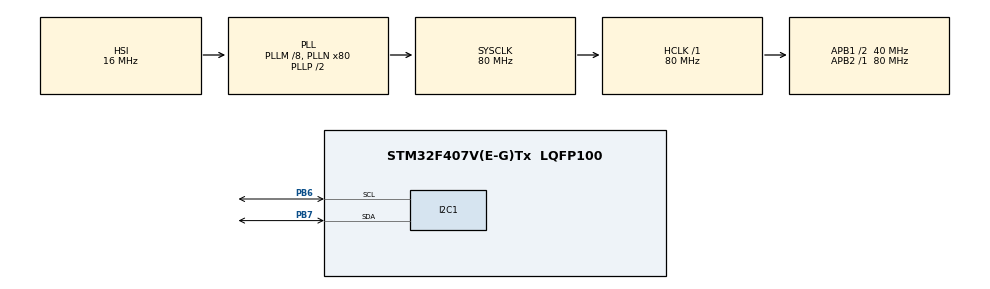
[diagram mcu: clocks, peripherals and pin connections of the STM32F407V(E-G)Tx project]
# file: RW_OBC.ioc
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Mcu.Family=STM32F4
Mcu.Name=STM32F407V(E-G)Tx
Mcu.Package=LQFP100
NVIC.PriorityGroup=NVIC_PRIORITYGROUP_4
PB6.Mode=I2C
PB6.Signal=I2C1_SCL
PB7.Mode=I2C
PB7.Signal=I2C1_SDA
ProjectManager.HeapSize=0x2000
ProjectManager.StackSize=0x4000
ProjectManager.TargetToolchain=STM32CubeIDE
RCC.48MHZClocksFreq_Value=22857142.85714286
RCC.AHBFreq_Value=80000000
RCC.APB1CLKDivider=RCC_HCLK_DIV2
RCC.APB1Freq_Value=40000000
RCC.APB1TimFreq_Value=80000000
RCC.APB2Freq_Value=80000000
RCC.APB2TimFreq_Value=80000000
RCC.CortexFreq_Value=80000000
RCC.HCLKFreq_Value=80000000
RCC.HSE_VALUE=8000000
RCC.HSI_VALUE=16000000
RCC.LSE_VALUE=32768
RCC.PLLM=8
RCC.PLLN=80
RCC.PLLQ=7
RCC.SYSCLKFreq_VALUE=80000000
RCC.SYSCLKSource=RCC_SYSCLKSOURCE_PLLCLK
RCC.VCOOutputFreq_Value=160000000
TIM1.Channel-Output\ Compare1\ No\ Output=TIM_CHANNEL_1
TIM1.Period=65536-1
TIM1.Prescaler=80-1
VP_TIM1_VS_no_output1.Mode=Output Compare1 No Output
board=custom

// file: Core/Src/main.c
/* USER CODE BEGIN Header */
/**
  ******************************************************************************
  * @file           : main.c
  * @brief          : Main program body
  ******************************************************************************
  * @attention
  *
  * <h2><center>&copy; Copyright (c) 2021 STMicroelectronics.
  * All rights reserved.</center></h2>
  *
  * This software component is licensed by ST under BSD 3-Clause license,
  * the "License"; You may not use this file except in compliance with the
  * License. You may obtain a copy of the License at:
  *                        opensource.org/licenses/BSD-3-Clause
  *
  ******************************************************************************
  */
/* USER CODE END Header */
#include "main.h"

I2C_HandleTypeDef hi2c1;

TIM_HandleTypeDef htim1;

/* USER CODE BEGIN PV */
L3GD20H_Type gyro;
HMC5883L_Type magn;
double psi;
double phi;
double test;
double theta;
Quaternion_Type q;
Rotation_Matrix_Type r;
/* USER CODE END PV */

void SystemClock_Config(void);
static void MX_GPIO_Init(void);
static void MX_I2C1_Init(void);
static void MX_TIM1_Init(void);

int main(void)
{

  /* MCU Configuration--------------------------------------------------------*/

  /* Reset of all peripherals, Initializes the Flash interface and the Systick. */
  HAL_Init();

  /* USER CODE BEGIN Init */

  float dt=0;
  /* USER CODE END Init */

  /* Configure the system clock */
  SystemClock_Config();

  /* Initialize all configured peripherals */
  MX_GPIO_Init();
  MX_I2C1_Init();
  MX_TIM1_Init();
  /* USER CODE BEGIN 2 */

  L3GD20H_Init(&gyro,hi2c1, L3GD20H_DR_200 ,L3GD20H_FR_250, L3GD20H_BW_3,L3GD20H_NORMAL,L3GD20H_LOW_ODR_D);
  HAL_TIM_Base_Start(&htim1);
  L3GD20H_Calibration(&gyro,htim1);

  /* USER CODE END 2 */

  /* Infinite loop */
  /* USER CODE BEGIN WHILE */
  __HAL_TIM_SET_COUNTER(&htim1, 0);
  HAL_Delay(10);
  while (1)
  {
    /* USER CODE END WHILE */

    /* USER CODE BEGIN 3 */
    dt=__HAL_TIM_GET_COUNTER(&htim1);
    dt=dt*0.000001;
	__HAL_TIM_SET_COUNTER(&htim1, 0);
	//  HMC5883L_Init(&magn,hi2c1);
	L3GD20H_Read(&gyro,dt);
	psi=gyro.angle[0]*3.1416/180;
	theta=gyro.angle[1]*3.1416/180;
	phi=gyro.angle[2]*3.1416/180;
	r=ADCS_RPY2RotationMatrix(phi,theta,psi);
	test=sqrt(r.r11+r.r22+r.r33+1);
	q=ADCS_RotationMatrix2Quaternion(&r);
	//HIL_Transmit_Gyro(&gyro);
	HAL_Delay(10);
  }
  /* USER CODE END 3 */
}

void SystemClock_Config(void)
{
  RCC_OscInitTypeDef RCC_OscInitStruct = {0};
  RCC_ClkInitTypeDef RCC_ClkInitStruct = {0};

  /** Configure the main internal regulator output voltage
  */
  __HAL_RCC_PWR_CLK_ENABLE();
  __HAL_PWR_VOLTAGESCALING_CONFIG(PWR_REGULATOR_VOLTAGE_SCALE1);
  /** Initializes the RCC Oscillators according to the specified parameters
  * in the RCC_OscInitTypeDef structure.
  */
  RCC_OscInitStruct.OscillatorType = RCC_OSCILLATORTYPE_HSI;
  RCC_OscInitStruct.HSIState = RCC_HSI_ON;
  RCC_OscInitStruct.HSICalibrationValue = RCC_HSICALIBRATION_DEFAULT;
  RCC_OscInitStruct.PLL.PLLState = RCC_PLL_ON;
  RCC_OscInitStruct.PLL.PLLSource = RCC_PLLSOURCE_HSI;
  RCC_OscInitStruct.PLL.PLLM = 8;
  RCC_OscInitStruct.PLL.PLLN = 80;
  RCC_OscInitStruct.PLL.PLLP = RCC_PLLP_DIV2;
  RCC_OscInitStruct.PLL.PLLQ = 7;
  if (HAL_RCC_OscConfig(&RCC_OscInitStruct) != HAL_OK)
  {
    Error_Handler();
  }
  /** Initializes the CPU, AHB and APB buses clocks
  */
  RCC_ClkInitStruct.ClockType = RCC_CLOCKTYPE_HCLK|RCC_CLOCKTYPE_SYSCLK
                              |RCC_CLOCKTYPE_PCLK1|RCC_CLOCKTYPE_PCLK2;
  RCC_ClkInitStruct.SYSCLKSource = RCC_SYSCLKSOURCE_PLLCLK;
  RCC_ClkInitStruct.AHBCLKDivider = RCC_SYSCLK_DIV1;
  RCC_ClkInitStruct.APB1CLKDivider = RCC_HCLK_DIV2;
  RCC_ClkInitStruct.APB2CLKDivider = RCC_HCLK_DIV1;

  if (HAL_RCC_ClockConfig(&RCC_ClkInitStruct, FLASH_LATENCY_2) != HAL_OK)
  {
    Error_Handler();
  }
}

static void MX_I2C1_Init(void)
{

  hi2c1.Instance = I2C1;
  hi2c1.Init.ClockSpeed = 100000;
  hi2c1.Init.DutyCycle = I2C_DUTYCYCLE_2;
  hi2c1.Init.OwnAddress1 = 0;
  hi2c1.Init.AddressingMode = I2C_ADDRESSINGMODE_7BIT;
  hi2c1.Init.DualAddressMode = I2C_DUALADDRESS_DISABLE;
  hi2c1.Init.OwnAddress2 = 0;
  hi2c1.Init.GeneralCallMode = I2C_GENERALCALL_DISABLE;
  hi2c1.Init.NoStretchMode = I2C_NOSTRETCH_DISABLE;
  if (HAL_I2C_Init(&hi2c1) != HAL_OK)
  {
    Error_Handler();
  }

}

static void MX_TIM1_Init(void)
{

  TIM_MasterConfigTypeDef sMasterConfig = {0};
  TIM_OC_InitTypeDef sConfigOC = {0};
  TIM_BreakDeadTimeConfigTypeDef sBreakDeadTimeConfig = {0};

  htim1.Instance = TIM1;
  htim1.Init.Prescaler = 80-1;
  htim1.Init.CounterMode = TIM_COUNTERMODE_UP;
  htim1.Init.Period = 65536-1;
  htim1.Init.ClockDivision = TIM_CLOCKDIVISION_DIV1;
  htim1.Init.RepetitionCounter = 0;
  htim1.Init.AutoReloadPreload = TIM_AUTORELOAD_PRELOAD_DISABLE;
  if (HAL_TIM_OC_Init(&htim1) != HAL_OK)
  {
    Error_Handler();
  }
  sMasterConfig.MasterOutputTrigger = TIM_TRGO_RESET;
  sMasterConfig.MasterSlaveMode = TIM_MASTERSLAVEMODE_DISABLE;
  if (HAL_TIMEx_MasterConfigSynchronization(&htim1, &sMasterConfig) != HAL_OK)
  {
    Error_Handler();
  }
  sConfigOC.OCMode = TIM_OCMODE_TIMING;
  sConfigOC.Pulse = 0;
  sConfigOC.OCPolarity = TIM_OCPOLARITY_HIGH;
  sConfigOC.OCNPolarity = TIM_OCNPOLARITY_HIGH;
  sConfigOC.OCFastMode = TIM_OCFAST_DISABLE;
  sConfigOC.OCIdleState = TIM_OCIDLESTATE_RESET;
  sConfigOC.OCNIdleState = TIM_OCNIDLESTATE_RESET;
  if (HAL_TIM_OC_ConfigChannel(&htim1, &sConfigOC, TIM_CHANNEL_1) != HAL_OK)
  {
    Error_Handler();
  }
  sBreakDeadTimeConfig.OffStateRunMode = TIM_OSSR_DISABLE;
  sBreakDeadTimeConfig.OffStateIDLEMode = TIM_OSSI_DISABLE;
  sBreakDeadTimeConfig.LockLevel = TIM_LOCKLEVEL_OFF;
  sBreakDeadTimeConfig.DeadTime = 0;
  sBreakDeadTimeConfig.BreakState = TIM_BREAK_DISABLE;
  sBreakDeadTimeConfig.BreakPolarity = TIM_BREAKPOLARITY_HIGH;
  sBreakDeadTimeConfig.AutomaticOutput = TIM_AUTOMATICOUTPUT_DISABLE;
  if (HAL_TIMEx_ConfigBreakDeadTime(&htim1, &sBreakDeadTimeConfig) != HAL_OK)
  {
    Error_Handler();
  }

}

static void MX_GPIO_Init(void)
{

  /* GPIO Ports Clock Enable */
  __HAL_RCC_GPIOB_CLK_ENABLE();

}

void Error_Handler(void)
{
  __disable_irq();
  while (1)
  {
  }
}

/************************ (C) COPYRIGHT STMicroelectronics *****END OF FILE****/
